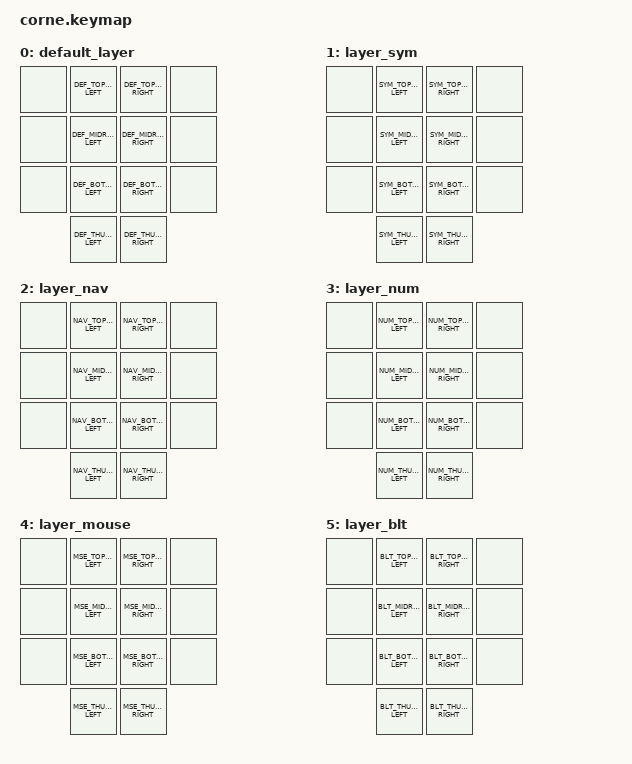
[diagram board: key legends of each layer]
/*
 * Copyright (c) 2020 The ZMK Contributors
 *
 * SPDX-License-Identifier: MIT
 */

#include <behaviors.dtsi>
#include <dt-bindings/zmk/keys.h>
#include <dt-bindings/zmk/bt.h>
#include <dt-bindings/zmk/mouse.h>
#include "../config_common/keymap.h"

/ {
  behaviors {
    #include "macros.dtsi"
    #include "version.dtsi"

    lhm: left_homerow_mods {
        flavor = "balanced";
        tapping-term-ms = <350>;    // <---[[moderate duration]]
        quick-tap-ms = <0>;
        require-prior-idle-ms = <150>;
        compatible = "zmk,behavior-hold-tap";
        #binding-cells = <2>;
        bindings = <&kp>, <&kp>;
        hold-trigger-key-positions = <KEYS_R THUMBS>;
        hold-trigger-on-release;
    };
    rhm: right_homerow_mods {
        flavor = "balanced";
        tapping-term-ms = <350>;    // <---[[moderate duration]]
        quick-tap-ms = <0>;
        require-prior-idle-ms = <150>;
        compatible = "zmk,behavior-hold-tap";
        #binding-cells = <2>;
        bindings = <&kp>, <&kp>;
        hold-trigger-key-positions = <KEYS_L THUMBS>;
        hold-trigger-on-release;
    };
    hm: homerow_mods {
        compatible = "zmk,behavior-hold-tap";
        label = "HOMEROW_MODS";
        #binding-cells = <2>;
        tapping-term-ms = <200>;
        quick_tap_ms = <175>;
        flavor = "balanced";
        bindings = <&kp>, <&kp>;
    };
  };
  combos {
      compatible = "zmk,combos";
      combo_esc {
          timeout-ms = <50>;
          key-positions = <LM3 LM4>;
          bindings = <&kp LC(LBKT)>;
      };
      combo_ae {
          timeout-ms = <50>;
          key-positions = <LT0 LT1>;
          bindings = <&kp RA(Q)>;
      };
      combo_oe {
          timeout-ms = <50>;
          key-positions = <LT1 LT2>;
          bindings = <&kp RA(P)>;
      };
      combo_ue {
          timeout-ms = <50>;
          key-positions = <LT2 LT3>;
          bindings = <&kp RA(Y)>;
      };
      combo_ss {
          timeout-ms = <50>;
          key-positions = <LT3 LT4>;
          bindings = <&kp RA(S)>;
      };
      combo_0 {
          timeout-ms = <50>;
          key-positions = <RB0 RB1>;
          bindings = <&kp N0>;
      };
      combo_1 {
          timeout-ms = <50>;
          key-positions = <RB1 RB2>;
          bindings = <&kp N1>;
      };
      combo_2 {
          timeout-ms = <50>;
          key-positions = <RB2 RB3>;
          bindings = <&kp N2>;
      };
      combo_3 {
          timeout-ms = <50>;
          key-positions = <RB3 RB4>;
          bindings = <&kp N3>;
      };
      combo_4 {
          timeout-ms = <50>;
          key-positions = <RM1 RM2>;
          bindings = <&kp N4>;
      };
      combo_5 {
          timeout-ms = <50>;
          key-positions = <RM2 RM3>;
          bindings = <&kp N5>;
      };
      combo_6 {
          timeout-ms = <50>;
          key-positions = <RM3 RM4>;
          bindings = <&kp N6>;
      };
      combo_7 {
          timeout-ms = <50>;
          key-positions = <RT1 RT2>;
          bindings = <&kp N7>;
      };
      combo_8 {
          timeout-ms = <50>;
          key-positions = <RT2 RT3>;
          bindings = <&kp N8>;
      };
      combo_9 {
          timeout-ms = <50>;
          key-positions = <RT3 RT4>;
          bindings = <&kp N9>;
      };
  };
  keymap {
                compatible = "zmk,keymap";

                default_layer {
                        bindings = <
   &none   DEF_TOPROW_LEFT      DEF_TOPROW_RIGHT    &none
   &none   DEF_MIDROW_LEFT      DEF_MIDROW_RIGHT    &none
   &none   DEF_BOTROW_LEFT      DEF_BOTROW_RIGHT    &none
           DEF_THUMBS_LEFT      DEF_THUMBS_RIGHT
                        >;
                };
                layer_sym {
                        bindings = <
   &none   SYM_TOPROW_LEFT      SYM_TOPROW_RIGHT    &none
   &none   SYM_MIDROW_LEFT      SYM_MIDROW_RIGHT    &none
   &none   SYM_BOTROW_LEFT      SYM_BOTROW_RIGHT    &none
           SYM_THUMBS_LEFT      SYM_THUMBS_RIGHT
                        >;
                };
                layer_nav {
                        bindings = <
   &none   NAV_TOPROW_LEFT      NAV_TOPROW_RIGHT    &none
   &none   NAV_MIDROW_LEFT      NAV_MIDROW_RIGHT    &none
   &none   NAV_BOTROW_LEFT      NAV_BOTROW_RIGHT    &none
           NAV_THUMBS_LEFT      NAV_THUMBS_RIGHT
                        >;
                };
                layer_num {
                        bindings = <
   &none   NUM_TOPROW_LEFT      NUM_TOPROW_RIGHT    &none
   &none   NUM_MIDROW_LEFT      NUM_MIDROW_RIGHT    &none
   &none   NUM_BOTROW_LEFT      NUM_BOTROW_RIGHT    &none
           NUM_THUMBS_LEFT      NUM_THUMBS_RIGHT
                        >;
                };
                layer_mouse {
                        bindings = <
   &none   MSE_TOPROW_LEFT      MSE_TOPROW_RIGHT    &none
   &none   MSE_MIDROW_LEFT      MSE_MIDROW_RIGHT    &none
   &none   MSE_BOTROW_LEFT      MSE_BOTROW_RIGHT    &none
           MSE_THUMBS_LEFT      MSE_THUMBS_RIGHT
                        >;
                };
                layer_blt {
                        bindings = <
   &none   BLT_TOPROW_LEFT      BLT_TOPROW_RIGHT    &none
   &none   BLT_MIDROW_LEFT      BLT_MIDROW_RIGHT    &none
   &none   BLT_BOTROW_LEFT      BLT_BOTROW_RIGHT    &none
           BLT_THUMBS_LEFT      BLT_THUMBS_RIGHT
                        >;
                };
        };
};
